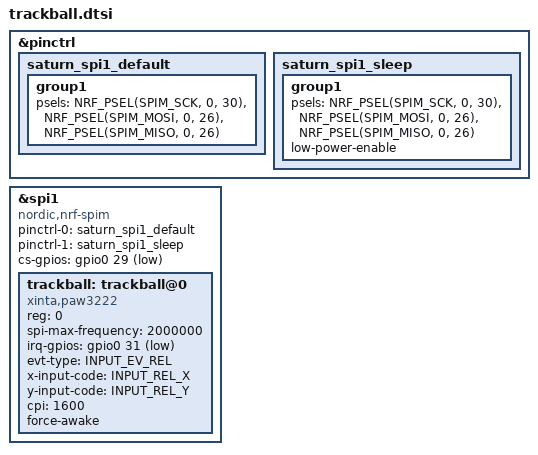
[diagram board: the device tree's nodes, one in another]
/*
 * PAW3222 trackball sensor on SPI1
 *
 * Wiring:
 *   SCLK  - P0.30
 *   SDIO  - P0.26  (MOSI/MISO share the bidirectional data line)
 *   NCS   - P0.29
 *   MOTION - P0.31 (irq)
 *
 * Note: the nrfmicro_13 board already defines spi1_default/spi1_sleep
 * pinctrl labels for its own SPI1 wiring, so this shield uses its own
 * labels and overrides the &spi1 pinctrl selection.
 */
#include <zephyr/dt-bindings/input/input-event-codes.h>

&pinctrl {
    saturn_spi1_default: saturn_spi1_default {
        group1 {
            psels = <NRF_PSEL(SPIM_SCK, 0, 30)>,
                <NRF_PSEL(SPIM_MOSI, 0, 26)>,
                <NRF_PSEL(SPIM_MISO, 0, 26)>;
        };
    };

    saturn_spi1_sleep: saturn_spi1_sleep {
        group1 {
            psels = <NRF_PSEL(SPIM_SCK, 0, 30)>,
                <NRF_PSEL(SPIM_MOSI, 0, 26)>,
                <NRF_PSEL(SPIM_MISO, 0, 26)>;
            low-power-enable;
        };
    };
};

&spi1 {
    status = "okay";
    compatible = "nordic,nrf-spim";
    pinctrl-0 = <&saturn_spi1_default>;
    pinctrl-1 = <&saturn_spi1_sleep>;
    pinctrl-names = "default", "sleep";
    cs-gpios = <&gpio0 29 GPIO_ACTIVE_LOW>;

    trackball: trackball@0 {
        status = "okay";
        compatible = "xinta,paw3222";
        reg = <0>;
        spi-max-frequency = <2000000>;
        irq-gpios = <&gpio0 31 (GPIO_ACTIVE_LOW | GPIO_PULL_UP)>;
        evt-type = <INPUT_EV_REL>;
        x-input-code = <INPUT_REL_X>;
        y-input-code = <INPUT_REL_Y>;
        cpi = <1600>;
        force-awake;
    };
};
